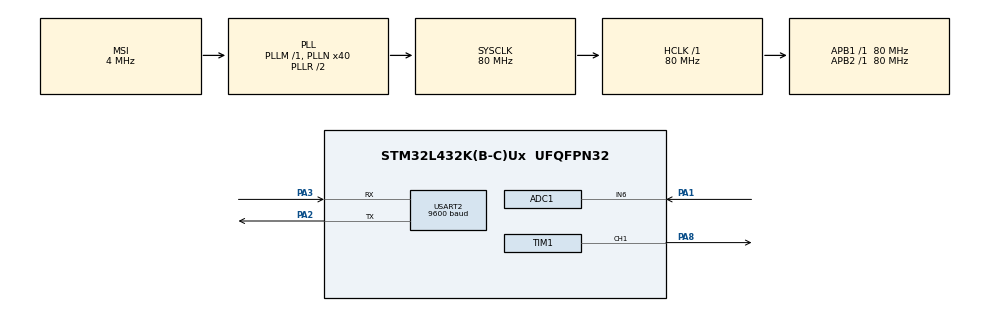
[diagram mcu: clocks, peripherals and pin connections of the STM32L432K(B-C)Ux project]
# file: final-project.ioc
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ADC1.Channel-1\#ChannelRegularConversion=ADC_CHANNEL_6
ADC1.ContinuousConvMode=DISABLE
ADC1.NbrOfConversionFlag=1
ADC1.OffsetNumber-1\#ChannelRegularConversion=ADC_OFFSET_NONE
ADC1.Rank-1\#ChannelRegularConversion=1
ADC1.SamplingTime-1\#ChannelRegularConversion=ADC_SAMPLETIME_2CYCLES_5
ADC1.master=1
Mcu.Family=STM32L4
Mcu.Name=STM32L432K(B-C)Ux
Mcu.Package=UFQFPN32
NVIC.PriorityGroup=NVIC_PRIORITYGROUP_4
NVIC.USART2_IRQn=true\:0\:0\:false\:false\:true\:true\:true
PA0.Mode=HSE-External-Clock-Source-for-LittleOrca
PA0.Signal=RCC_CK_IN
PA1.Signal=ADCx_IN6
PA13\ (JTMS-SWDIO).Mode=Serial_Wire
PA13\ (JTMS-SWDIO).Signal=SYS_JTMS-SWDIO
PA14\ (JTCK-SWCLK).Mode=Serial_Wire
PA14\ (JTCK-SWCLK).Signal=SYS_JTCK-SWCLK
PA2.Mode=Asynchronous
PA2.Signal=USART2_TX
PA3.Mode=Asynchronous
PA3.Signal=USART2_RX
PA8.Signal=S_TIM1_CH1
ProjectManager.HeapSize=0x200
ProjectManager.StackSize=0x400
ProjectManager.TargetToolchain=MDK-ARM V5
RCC.ADCFreq_Value=32000000
RCC.AHBFreq_Value=80000000
RCC.APB1Freq_Value=80000000
RCC.APB1TimFreq_Value=80000000
RCC.APB2Freq_Value=80000000
RCC.APB2TimFreq_Value=80000000
RCC.CortexFreq_Value=80000000
RCC.HCLKFreq_Value=80000000
RCC.HSE_VALUE=8000000
RCC.HSI48_VALUE=48000000
RCC.HSI_VALUE=16000000
RCC.LSE_VALUE=32768
RCC.MSI_VALUE=4000000
RCC.PLLN=40
RCC.PLLSAI1N=16
RCC.SYSCLKFreq_VALUE=80000000
RCC.SYSCLKSource=RCC_SYSCLKSOURCE_PLLCLK
RCC.USBFreq_Value=32000000
RCC.VCOOutputFreq_Value=160000000
SH.ADCx_IN6.0=ADC1_IN6,IN6-Single-Ended
SH.S_TIM1_CH1.0=TIM1_CH1,PWM Generation1 CH1
TIM1.Channel-PWM\ Generation1\ CH1=TIM_CHANNEL_1
TIM1.Period=99
TIM1.Prescaler=79
USART2.BaudRate=9600
USART2.VirtualMode-Asynchronous=VM_ASYNC
VP_TIM1_VS_ClockSourceINT.Mode=Internal
VP_TIM1_VS_ClockSourceITR.Mode=TriggerSource_ITR0
board=custom

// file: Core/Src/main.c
/* USER CODE BEGIN Header */
/**
  ******************************************************************************
  * @file           : main.c
  * @brief          : Main program body
  ******************************************************************************
  * @attention
  *
  * <h2><center>&copy; Copyright (c) 2020 STMicroelectronics.
  * All rights reserved.</center></h2>
  *
  * This software component is licensed by ST under BSD 3-Clause license,
  * the "License"; You may not use this file except in compliance with the
  * License. You may obtain a copy of the License at:
  *                        opensource.org/licenses/BSD-3-Clause
  *
  ******************************************************************************
  */
/* USER CODE END Header */
#include "main.h"
#include "stdlib.h"
#include "stdio.h"

/* USER CODE BEGIN Includes */
uint16_t ADC=0;
static int counter=0;
/* USER CODE END Includes */

/* USER CODE BEGIN PTD */
	void HAL_ADC_ConvCpltCallback(ADC_HandleTypeDef* hadc);
/* USER CODE END PTD */

ADC_HandleTypeDef hadc1;
DMA_HandleTypeDef hdma_adc1;

TIM_HandleTypeDef htim1;

UART_HandleTypeDef huart2;

void SystemClock_Config(void);
static void MX_GPIO_Init(void);
static void MX_DMA_Init(void);
static void MX_USART2_UART_Init(void);
static void MX_TIM1_Init(void);
static void MX_ADC1_Init(void);

/* USER CODE BEGIN 0 */
/*
void SysTick_Handler(void)
{
	counter++;
}
*/

/* USER CODE END 0 */

int main(void)
{
  /* USER CODE BEGIN 1 */
	char str[30];
	char str2[30];
	uint16_t ADC_buffer[1000];

  /* USER CODE END 1 */

  /* MCU Configuration--------------------------------------------------------*/

  /* Reset of all peripherals, Initializes the Flash interface and the Systick. */
  HAL_Init();

  /* Configure the system clock */
  SystemClock_Config();

  /* Initialize all configured peripherals */
  MX_GPIO_Init();
  MX_DMA_Init();
  MX_USART2_UART_Init();
  MX_TIM1_Init();
  MX_ADC1_Init();
  /* USER CODE BEGIN 2 */
//s	HAL_ADC_Start_IT(&hadc1);
  /* USER CODE END 2 */
//HAL ADC START
 //HAL_ADC_Start(&hadc1);
// ADC CONVERSION POLLING

  /* Infinite loop */
  while (1)
  {

 HAL_ADC_Start(&hadc1);
    /* USER CODE BEGIN 3 */

		if (HAL_ADC_PollForConversion(&hadc1, HAL_MAX_DELAY) == HAL_OK) {
        ADC = HAL_ADC_GetValue(&hadc1);
			counter++;
			sprintf(str2,"T%d\n",counter);
			sprintf(str,"R%d",ADC);

			HAL_UART_Transmit(&huart2, (uint8_t*)&str,sizeof(str),HAL_MAX_DELAY);
			HAL_UART_Transmit(&huart2, (uint8_t*)&str2,sizeof(str2),HAL_MAX_DELAY);
    } else {
       //
    }

  }
  /* USER CODE END 3 */
}
void HAL_ADC_ConvCpltCallback(ADC_HandleTypeDef* hadc)
{
    ADC = HAL_ADC_GetValue(&hadc1);
}
void SystemClock_Config(void)
{
  RCC_OscInitTypeDef RCC_OscInitStruct = {0};
  RCC_ClkInitTypeDef RCC_ClkInitStruct = {0};
  RCC_PeriphCLKInitTypeDef PeriphClkInit = {0};

  /** Initializes the RCC Oscillators according to the specified parameters
  * in the RCC_OscInitTypeDef structure.
  */
  RCC_OscInitStruct.OscillatorType = RCC_OSCILLATORTYPE_MSI;
  RCC_OscInitStruct.MSIState = RCC_MSI_ON;
  RCC_OscInitStruct.MSICalibrationValue = 0;
  RCC_OscInitStruct.MSIClockRange = RCC_MSIRANGE_6;
  RCC_OscInitStruct.PLL.PLLState = RCC_PLL_ON;
  RCC_OscInitStruct.PLL.PLLSource = RCC_PLLSOURCE_MSI;
  RCC_OscInitStruct.PLL.PLLM = 1;
  RCC_OscInitStruct.PLL.PLLN = 40;
  RCC_OscInitStruct.PLL.PLLP = RCC_PLLP_DIV7;
  RCC_OscInitStruct.PLL.PLLQ = RCC_PLLQ_DIV2;
  RCC_OscInitStruct.PLL.PLLR = RCC_PLLR_DIV2;
  if (HAL_RCC_OscConfig(&RCC_OscInitStruct) != HAL_OK)
  {
    Error_Handler();
  }
  /** Initializes the CPU, AHB and APB buses clocks
  */
  RCC_ClkInitStruct.ClockType = RCC_CLOCKTYPE_HCLK|RCC_CLOCKTYPE_SYSCLK
                              |RCC_CLOCKTYPE_PCLK1|RCC_CLOCKTYPE_PCLK2;
  RCC_ClkInitStruct.SYSCLKSource = RCC_SYSCLKSOURCE_PLLCLK;
  RCC_ClkInitStruct.AHBCLKDivider = RCC_SYSCLK_DIV1;
  RCC_ClkInitStruct.APB1CLKDivider = RCC_HCLK_DIV1;
  RCC_ClkInitStruct.APB2CLKDivider = RCC_HCLK_DIV1;

  if (HAL_RCC_ClockConfig(&RCC_ClkInitStruct, FLASH_LATENCY_4) != HAL_OK)
  {
    Error_Handler();
  }
  PeriphClkInit.PeriphClockSelection = RCC_PERIPHCLK_USART2|RCC_PERIPHCLK_ADC;
  PeriphClkInit.Usart2ClockSelection = RCC_USART2CLKSOURCE_PCLK1;
  PeriphClkInit.AdcClockSelection = RCC_ADCCLKSOURCE_PLLSAI1;
  PeriphClkInit.PLLSAI1.PLLSAI1Source = RCC_PLLSOURCE_MSI;
  PeriphClkInit.PLLSAI1.PLLSAI1M = 1;
  PeriphClkInit.PLLSAI1.PLLSAI1N = 16;
  PeriphClkInit.PLLSAI1.PLLSAI1P = RCC_PLLP_DIV7;
  PeriphClkInit.PLLSAI1.PLLSAI1Q = RCC_PLLQ_DIV2;
  PeriphClkInit.PLLSAI1.PLLSAI1R = RCC_PLLR_DIV2;
  PeriphClkInit.PLLSAI1.PLLSAI1ClockOut = RCC_PLLSAI1_ADC1CLK;
  if (HAL_RCCEx_PeriphCLKConfig(&PeriphClkInit) != HAL_OK)
  {
    Error_Handler();
  }
  /** Configure the main internal regulator output voltage
  */
  if (HAL_PWREx_ControlVoltageScaling(PWR_REGULATOR_VOLTAGE_SCALE1) != HAL_OK)
  {
    Error_Handler();
  }
}

static void MX_ADC1_Init(void)
{

  ADC_ChannelConfTypeDef sConfig = {0};

  /** Common config
  */
  hadc1.Instance = ADC1;
  hadc1.Init.ClockPrescaler = ADC_CLOCK_ASYNC_DIV1;
  hadc1.Init.Resolution = ADC_RESOLUTION_12B;
  hadc1.Init.DataAlign = ADC_DATAALIGN_RIGHT;
  hadc1.Init.ScanConvMode = ADC_SCAN_DISABLE;
  hadc1.Init.EOCSelection = ADC_EOC_SINGLE_CONV;
  hadc1.Init.LowPowerAutoWait = DISABLE;
  hadc1.Init.ContinuousConvMode = DISABLE;
  hadc1.Init.NbrOfConversion = 1;
  hadc1.Init.DiscontinuousConvMode = DISABLE;
  hadc1.Init.ExternalTrigConv = ADC_SOFTWARE_START;
  hadc1.Init.ExternalTrigConvEdge = ADC_EXTERNALTRIGCONVEDGE_NONE;
  hadc1.Init.DMAContinuousRequests = DISABLE;
  hadc1.Init.Overrun = ADC_OVR_DATA_PRESERVED;
  hadc1.Init.OversamplingMode = DISABLE;
  if (HAL_ADC_Init(&hadc1) != HAL_OK)
  {
    Error_Handler();
  }
  /** Configure Regular Channel
  */
  sConfig.Channel = ADC_CHANNEL_6;
  sConfig.Rank = ADC_REGULAR_RANK_1;
  sConfig.SamplingTime = ADC_SAMPLETIME_2CYCLES_5;
  sConfig.SingleDiff = ADC_SINGLE_ENDED;
  sConfig.OffsetNumber = ADC_OFFSET_NONE;
  sConfig.Offset = 0;
  if (HAL_ADC_ConfigChannel(&hadc1, &sConfig) != HAL_OK)
  {
    Error_Handler();
  }

}

static void MX_TIM1_Init(void)
{

  TIM_ClockConfigTypeDef sClockSourceConfig = {0};
  TIM_SlaveConfigTypeDef sSlaveConfig = {0};
  TIM_MasterConfigTypeDef sMasterConfig = {0};
  TIM_OC_InitTypeDef sConfigOC = {0};
  TIM_BreakDeadTimeConfigTypeDef sBreakDeadTimeConfig = {0};

  htim1.Instance = TIM1;
  htim1.Init.Prescaler = 79;
  htim1.Init.CounterMode = TIM_COUNTERMODE_UP;
  htim1.Init.Period = 99;
  htim1.Init.ClockDivision = TIM_CLOCKDIVISION_DIV1;
  htim1.Init.RepetitionCounter = 0;
  htim1.Init.AutoReloadPreload = TIM_AUTORELOAD_PRELOAD_DISABLE;
  if (HAL_TIM_Base_Init(&htim1) != HAL_OK)
  {
    Error_Handler();
  }
  sClockSourceConfig.ClockSource = TIM_CLOCKSOURCE_INTERNAL;
  if (HAL_TIM_ConfigClockSource(&htim1, &sClockSourceConfig) != HAL_OK)
  {
    Error_Handler();
  }
  if (HAL_TIM_PWM_Init(&htim1) != HAL_OK)
  {
    Error_Handler();
  }
  sSlaveConfig.SlaveMode = TIM_SLAVEMODE_DISABLE;
  sSlaveConfig.InputTrigger = TIM_TS_ITR0;
  if (HAL_TIM_SlaveConfigSynchro(&htim1, &sSlaveConfig) != HAL_OK)
  {
    Error_Handler();
  }
  sMasterConfig.MasterOutputTrigger = TIM_TRGO_RESET;
  sMasterConfig.MasterOutputTrigger2 = TIM_TRGO2_RESET;
  sMasterConfig.MasterSlaveMode = TIM_MASTERSLAVEMODE_DISABLE;
  if (HAL_TIMEx_MasterConfigSynchronization(&htim1, &sMasterConfig) != HAL_OK)
  {
    Error_Handler();
  }
  sConfigOC.OCMode = TIM_OCMODE_PWM1;
  sConfigOC.Pulse = 0;
  sConfigOC.OCPolarity = TIM_OCPOLARITY_HIGH;
  sConfigOC.OCNPolarity = TIM_OCNPOLARITY_HIGH;
  sConfigOC.OCFastMode = TIM_OCFAST_DISABLE;
  sConfigOC.OCIdleState = TIM_OCIDLESTATE_RESET;
  sConfigOC.OCNIdleState = TIM_OCNIDLESTATE_RESET;
  if (HAL_TIM_PWM_ConfigChannel(&htim1, &sConfigOC, TIM_CHANNEL_1) != HAL_OK)
  {
    Error_Handler();
  }
  sBreakDeadTimeConfig.OffStateRunMode = TIM_OSSR_DISABLE;
  sBreakDeadTimeConfig.OffStateIDLEMode = TIM_OSSI_DISABLE;
  sBreakDeadTimeConfig.LockLevel = TIM_LOCKLEVEL_OFF;
  sBreakDeadTimeConfig.DeadTime = 0;
  sBreakDeadTimeConfig.BreakState = TIM_BREAK_DISABLE;
  sBreakDeadTimeConfig.BreakPolarity = TIM_BREAKPOLARITY_HIGH;
  sBreakDeadTimeConfig.BreakFilter = 0;
  sBreakDeadTimeConfig.Break2State = TIM_BREAK2_DISABLE;
  sBreakDeadTimeConfig.Break2Polarity = TIM_BREAK2POLARITY_HIGH;
  sBreakDeadTimeConfig.Break2Filter = 0;
  sBreakDeadTimeConfig.AutomaticOutput = TIM_AUTOMATICOUTPUT_DISABLE;
  if (HAL_TIMEx_ConfigBreakDeadTime(&htim1, &sBreakDeadTimeConfig) != HAL_OK)
  {
    Error_Handler();
  }
  HAL_TIM_MspPostInit(&htim1);

}

static void MX_USART2_UART_Init(void)
{

  huart2.Instance = USART2;
  huart2.Init.BaudRate = 9600;
  huart2.Init.WordLength = UART_WORDLENGTH_8B;
  huart2.Init.StopBits = UART_STOPBITS_1;
  huart2.Init.Parity = UART_PARITY_NONE;
  huart2.Init.Mode = UART_MODE_TX_RX;
  huart2.Init.HwFlowCtl = UART_HWCONTROL_NONE;
  huart2.Init.OverSampling = UART_OVERSAMPLING_16;
  huart2.Init.OneBitSampling = UART_ONE_BIT_SAMPLE_DISABLE;
  huart2.AdvancedInit.AdvFeatureInit = UART_ADVFEATURE_NO_INIT;
  if (HAL_UART_Init(&huart2) != HAL_OK)
  {
    Error_Handler();
  }

}

static void MX_DMA_Init(void)
{

  /* DMA controller clock enable */
  __HAL_RCC_DMA1_CLK_ENABLE();

  /* DMA interrupt init */
  /* DMA1_Channel1_IRQn interrupt configuration */
  HAL_NVIC_SetPriority(DMA1_Channel1_IRQn, 0, 0);
  HAL_NVIC_EnableIRQ(DMA1_Channel1_IRQn);

}

static void MX_GPIO_Init(void)
{

  /* GPIO Ports Clock Enable */
  __HAL_RCC_GPIOA_CLK_ENABLE();

}

void Error_Handler(void)
{
}

/************************ (C) COPYRIGHT STMicroelectronics *****END OF FILE****/
